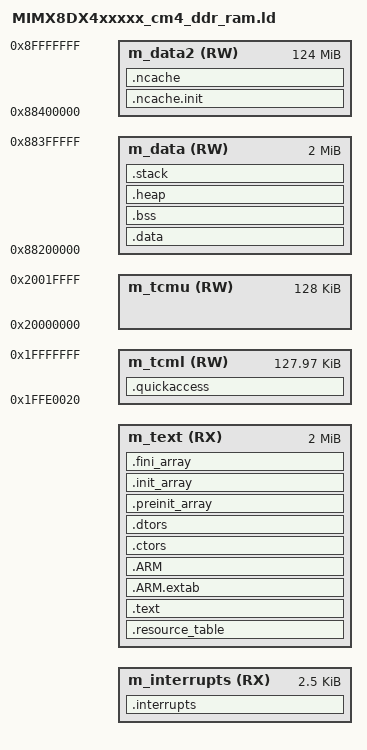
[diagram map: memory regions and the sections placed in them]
/*
** ###################################################################
**     Processor:           MIMX8DX4AVLFZ
**     Compiler:            GNU C Compiler
**     Reference manual:    IMX8DQXPRM, Rev. E, 6/2019
**     Version:             rev. 4.0, 2020-06-19
**     Build:               b201113
**
**     Abstract:
**         Linker file for the GNU C Compiler
**
**     Copyright 2016 Freescale Semiconductor, Inc.
**     Copyright 2016-2020 NXP
**     All rights reserved.
**
**     SPDX-License-Identifier: BSD-3-Clause
**
**     http:                 www.nxp.com
**     mail:                 support@nxp.com
**
** ###################################################################
*/

/* Entry Point */
ENTRY(Reset_Handler)

HEAP_SIZE  = DEFINED(__heap_size__)  ? __heap_size__  : 0x0400;
STACK_SIZE = DEFINED(__stack_size__) ? __stack_size__ : 0x0400;

/* Reserved for PFU fetches, which is six 16-bit Thumb instructions */
SAFE_BOUNDARY_LEN = 12;

/* Specify the memory areas */
/* M4 always start up from TCM. The SCU will copy the first 32 bytes of the binary to TCM
if the start address is not TCM. The TCM region [0x1FFE0000-0x1FFE001F] is reserved for this purpose. */
MEMORY
{
  m_interrupts          (RX)  : ORIGIN = DEFINED(__STARTUP_CONFIG_DDR_ALIAS)?0x08000000:0x88000000, LENGTH = 0x00000A00
  m_text                (RX)  : ORIGIN = DEFINED(__STARTUP_CONFIG_DDR_ALIAS)?0x08000A00:0x88000A00, LENGTH = 0x001FF600
  m_data                (RW)  : ORIGIN = 0x88200000, LENGTH = 0x00200000
  m_data2               (RW)  : ORIGIN = 0x88400000, LENGTH = 0x07C00000
  m_tcml                (RW)  : ORIGIN = 0x1FFE0020, LENGTH = 0x0001FFE0
  m_tcmu                (RW)  : ORIGIN = 0x20000000, LENGTH = 0x00020000
}

/* Define output sections */
SECTIONS
{
  /* The startup code goes first into internal RAM */
  .interrupts :
  {
    . = ALIGN(4);
    KEEP(*(.isr_vector))     /* Startup code */
    . = ALIGN(4);
  } > m_interrupts

  .resource_table :
  {
    . = ALIGN(8);
    KEEP(*(.resource_table)) /* Resource table */
    . = ALIGN(8);
  } > m_text

  /* The program code and other data goes into internal RAM */
  .text :
  {
    . = ALIGN(4);
    *(.text)                 /* .text sections (code) */
    *(.text*)                /* .text* sections (code) */
    *(.rodata)               /* .rodata sections (constants, strings, etc.) */
    *(.rodata*)              /* .rodata* sections (constants, strings, etc.) */
    *(.glue_7)               /* glue arm to thumb code */
    *(.glue_7t)              /* glue thumb to arm code */
    *(.eh_frame)
    KEEP (*(.init))
    KEEP (*(.fini))
    . = ALIGN(4);
  } > m_text

  .ARM.extab :
  {
    *(.ARM.extab* .gnu.linkonce.armextab.*)
  } > m_text

  .ARM :
  {
    __exidx_start = .;
    *(.ARM.exidx*)
    __exidx_end = .;
  } > m_text

 .ctors :
  {
    __CTOR_LIST__ = .;
    /* gcc uses crtbegin.o to find the start of
       the constructors, so we make sure it is
       first.  Because this is a wildcard, it
       doesn't matter if the user does not
       actually link against crtbegin.o; the
       linker won't look for a file to match a
       wildcard.  The wildcard also means that it
       doesn't matter which directory crtbegin.o
       is in.  */
    KEEP (*crtbegin.o(.ctors))
    KEEP (*crtbegin?.o(.ctors))
    /* We don't want to include the .ctor section from
       from the crtend.o file until after the sorted ctors.
       The .ctor section from the crtend file contains the
       end of ctors marker and it must be last */
    KEEP (*(EXCLUDE_FILE(*crtend?.o *crtend.o) .ctors))
    KEEP (*(SORT(.ctors.*)))
    KEEP (*(.ctors))
    __CTOR_END__ = .;
  } > m_text

  .dtors :
  {
    __DTOR_LIST__ = .;
    KEEP (*crtbegin.o(.dtors))
    KEEP (*crtbegin?.o(.dtors))
    KEEP (*(EXCLUDE_FILE(*crtend?.o *crtend.o) .dtors))
    KEEP (*(SORT(.dtors.*)))
    KEEP (*(.dtors))
    __DTOR_END__ = .;
  } > m_text

  .preinit_array :
  {
    PROVIDE_HIDDEN (__preinit_array_start = .);
    KEEP (*(.preinit_array*))
    PROVIDE_HIDDEN (__preinit_array_end = .);
  } > m_text

  .init_array :
  {
    PROVIDE_HIDDEN (__init_array_start = .);
    KEEP (*(SORT(.init_array.*)))
    KEEP (*(.init_array*))
    PROVIDE_HIDDEN (__init_array_end = .);
  } > m_text

  .fini_array :
  {
    PROVIDE_HIDDEN (__fini_array_start = .);
    KEEP (*(SORT(.fini_array.*)))
    KEEP (*(.fini_array*))
    PROVIDE_HIDDEN (__fini_array_end = .);
  } > m_text

  __etext = .;    /* define a global symbol at end of code */
  __DATA_ROM = .; /* Symbol is used by startup for data initialization */

  .data : AT(__DATA_ROM)
  {
    . = ALIGN(4);
    __DATA_RAM = .;
    __data_start__ = .;      /* create a global symbol at data start */
    *(.data)                 /* .data sections */
    *(.data*)                /* .data* sections */
    KEEP(*(.jcr*))
    . = ALIGN(4);
    __data_end__ = .;        /* define a global symbol at data end */
  } > m_data

  __TDATA_ROM = __DATA_ROM + SIZEOF(.data); /* Symbol is used by startup for TCM data initialization */
  .quickaccess : AT(__TDATA_ROM)
  {
    __quickaccess_start__ = .;
    . = ALIGN(32);
    *(CodeQuickAccess)
    . += SAFE_BOUNDARY_LEN;
    *(DataQuickAccess)
    . = ALIGN(128);
    __quickaccess_end__ = .;
  } > m_tcml

  __CACHE_REGION_START = DEFINED(__STARTUP_CONFIG_DDR_ALIAS) ? ORIGIN(m_data) : ORIGIN(m_interrupts);
  __CACHE_REGION_SIZE = DEFINED(__STARTUP_CONFIG_DDR_ALIAS) ? LENGTH(m_data) : LENGTH(m_interrupts) + LENGTH(m_text) + LENGTH(m_data);


  __NDATA_ROM = __TDATA_ROM + SIZEOF(.quickaccess); /* Symbol is used by startup for ncache data initialization */

  .ncache.init : AT(__NDATA_ROM)
  {
    __noncachedata_start__ = .;   /* create a global symbol at ncache data start */
    *(NonCacheable.init)
    . = ALIGN(4);
    __noncachedata_init_end__ = .;   /* create a global symbol at initialized ncache data end */
  } > m_data2

  . = __noncachedata_init_end__;
  .ncache :
  {
    *(NonCacheable)
    . = ALIGN(4);
    __noncachedata_end__ = .;     /* define a global symbol at ncache data end */
  } > m_data2

  __DATA_END = __NDATA_ROM + SIZEOF(.ncache.init);
  text_end = ORIGIN(m_text) + LENGTH(m_text);
  ASSERT(__DATA_END <= text_end, "region m_text overflowed with text and data")

  /* Uninitialized data section */
  .bss :
  {
    /* This is used by the startup in order to initialize the .bss section */
    . = ALIGN(4);
    __START_BSS = .;
    __bss_start__ = .;
    *(.bss)
    *(.bss*)
    *(COMMON)
    . = ALIGN(4);
    __bss_end__ = .;
    __END_BSS = .;
  } > m_data

  .heap :
  {
    . = ALIGN(8);
    __end__ = .;
    PROVIDE(end = .);
    __HeapBase = .;
    . += HEAP_SIZE;
    __HeapLimit = .;
    __heap_limit = .; /* Add for _sbrk */
  } > m_data

  .stack :
  {
    . = ALIGN(8);
    . += STACK_SIZE;
  } > m_data

  /* Initializes stack on the end of block */
  __StackTop   = ORIGIN(m_data) + LENGTH(m_data);
  __StackLimit = __StackTop - STACK_SIZE;
  PROVIDE(__stack = __StackTop);

  .ARM.attributes 0 : { *(.ARM.attributes) }

  ASSERT(__StackLimit >= __HeapLimit, "region m_data overflowed with stack and heap")
}

